# PN73xxAU register map
File version: 2
CPU: CM0 r0p0, little endian, no MPU, no FPU, 2 interrupt priority bits
Registers are 32-bit, read-write, reset 0x0 unless marked. A register's access mark holds for its fields unless they carry their own. Offsets are from the block's base; [hi:lo] are bit positions; {n}, {i} and the like mark numbered series.

## CLIF (part 2 of 2) — Contactless Interface Frontend
Base 0x40004000
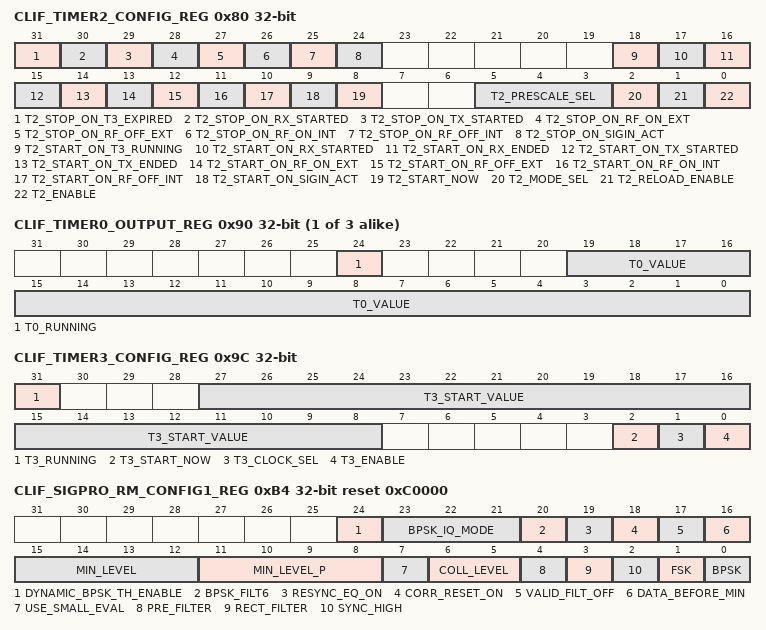
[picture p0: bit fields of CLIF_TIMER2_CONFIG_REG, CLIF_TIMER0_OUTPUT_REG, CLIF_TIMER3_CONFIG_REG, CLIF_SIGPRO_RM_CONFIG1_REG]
0x80 CLIF_TIMER2_CONFIG_REG — CLTimer register
  [31] T2_STOP_ON_T3_EXPIRED — T2_STOP_EVENT: If set. the timer T2 is stopped when timer T3 raises its expiration flag.
  [30] T2_STOP_ON_RX_STARTED — T2_STOP_EVENT: If set. the timer T2 is stopped when a data reception begins (1st bit is received).
  [29] T2_STOP_ON_TX_STARTED — T2_STOP_EVENT: If set. the timer T2 is stopped when a data transmission begins.
  [28] T2_STOP_ON_RF_ON_EXT — T2_STOP_EVENT: If set. the timer T2 is stopped when the external RF field is detected.
  [27] T2_STOP_ON_RF_OFF_EXT — T2_STOP_EVENT: If set. the timer T2 is stopped when the external RF field vanishes.
  [26] T2_STOP_ON_RF_ON_INT — T2_STOP_EVENT: If set. the timer T2 is stopped when the internal RF field is turned on.
  [25] T2_STOP_ON_RF_OFF_INT — T2_STOP_EVENT: If set. the timer T2 is stopped when the internal RF field is turned off.
  [24] T2_STOP_ON_SIGIN_ACT — T2_STOP_EVENT: If set. the timer T2 is stopped when an activity on SigIn is detected.
  [18] T2_START_ON_T3_RUNNING — T2_START_EVENT: If set. the timer T2 is started when timer T3 has started.
  [17] T2_START_ON_RX_STARTED — T2_START_EVENT: If set. the timer T2 is started when a data reception begins (1st bit is received).
  [16] T2_START_ON_RX_ENDED — T2_START_EVENT: If set. the timer T2 is started when a data reception ends.
  [15] T2_START_ON_TX_STARTED — T2_START_EVENT: If set. the timer T2 is started when a data transmission begins.
  [14] T2_START_ON_TX_ENDED — T2_START_EVENT: If set. the timer T2 is started when a data transmission ends.
  [13] T2_START_ON_RF_ON_EXT — T2_START_EVENT: If set. the timer T2 is started when the external RF field is detected.
  [12] T2_START_ON_RF_OFF_EXT — T2_START_EVENT: If set. the timer T2 is started when the external RF field is not detected any more.
  [11] T2_START_ON_RF_ON_INT — T2_START_EVENT: If set. the timer T2 is started when an internal RF field is turned on.
  [10] T2_START_ON_RF_OFF_INT — T2_START_EVENT: If set. the timer T2 is started when an internal RF field is turned off.
  [9] T2_START_ON_SIGIN_ACT — T2_START_EVENT: If set. the timer T2 is started when an activity on SigIn is detected.
  [8] T2_START_NOW — T2_START_EVENT: If set. the timer T2 is started immediatly.
  [5:3] T2_PRESCALE_SEL — Controls frequency/period of the timer T2 when the prescaler is activated by T2_MODE_SEL. 000b* 6.78MHz counter 001b 3.39MHz counter 010b 1.70MHz counter 011b 848kHz counter 100b 424kHz counter 101b 212kHz counter 110b 106kHz counter 111b 53kHz counter
  [2] T2_MODE_SEL — If set. the timer T2 is started the prescaler for the timer T2 is enabled. 0* Prescaler is disabled: the timer frequency matches CLIF clock frequency (13.56MHz). 1 Prescaler is enabled: the timer operates on the prescaler signal frequency (chosen by T2_PRESCALE_SEL).
  [1] T2_RELOAD_ENABLE — If set to 0.the timer T2 will stop on expiration. 0* After expiration the timer T2 will stop counting. i.e.. remain zero. reset value. 1 After expiration the timer T2 will reload its preset value and continue counting down.
  [0] T2_ENABLE — Enables the timer T2
{0x84+4i} CLIF_TIMER{i}_RELOAD_REG (i=0..2) — CLTimer register
  [19:0] T{i}_RELOAD_VALUE — Reload value of the timer T{i}.
{0x90+4i} CLIF_TIMER{i}_OUTPUT_REG ro (i=0..2) — CLTimer register
  [24] T{i}_RUNNING — Indicates that timer T{i} is running (busy)
  [19:0] T{i}_VALUE — Value of 20bit counter in timer T{i}
0x9C CLIF_TIMER3_CONFIG_REG — CLTimer register
  [31] T3_RUNNING ro — Indicates that timer T3 is running (busy)
  [27:8] T3_START_VALUE — Start value of timer T3
  [2] T3_START_NOW — Start event for T3
  [1] T3_CLOCK_SEL — Select the timer clock frequency 0 HFO clock 1 LFO clock
  [0] T3_ENABLE — Enables timer T3
0xAC CLIF_SIGPRO_CONFIG_REG — SigPro register
  [31:0] INTERNAL_USE_0_31 — Internal Use
0xB0 CLIF_SIGPRO_RM_CONFIG0_REG — SigPro register
  [31:0] INTERNAL_USE_0_31 — Internal Use
0xB4 CLIF_SIGPRO_RM_CONFIG1_REG reset 0xC0000 — SigPro register
  [24] DYNAMIC_BPSK_TH_ENABLE — If set to 1 the threshold for BPSK demodulation is dynamically adapted while reception. Note: This setting is only valid in BSPK modes - otherwise it is ignored
  [23:21] BPSK_IQ_MODE — 000*-111 Defines strategy of signal processing regarding I and Q channel 000* Both channels (I and Q) are used for signal processing 001 Use only I channel 010 Use only Q channel 011 RFU 100 Use the strongest channel 101 Use the first channel 110-111 RFU
  [20] BPSK_FILT6 — This bit changes the Spike filter for the Phaseshift detection from order 5 to order 6 (default = order 6).
  [19] RESYNC_EQ_ON — Resynchronisaton during the SOF for an equal correlation value is done (default = activated).
  [18] CORR_RESET_ON — The correclator is reset at a reset (default = activated).
  [17] VALID_FILT_OFF — Disables a special filter in BPSK mode. If set to 0 the correlation of 0110 is filtered with the correlation of 1110 and 0111. Otherwise the demodulation is done using the correlation with 0110
  [16] DATA_BEFORE_MIN — Data is received even before the first minimum at the SOF (default: = deactivated).
  [15:12] MIN_LEVEL — Defines the MinLevel of the reception Note: The MinLevel should be higher than the noise level in the system Note: Used for BPSK and Manchester with Subcarrier communication types as MinLevel!
  [11:8] MIN_LEVEL_P — Defines the minlevel for the phaseshift detector unit
  [7] USE_SMALL_EVAL — Defines the length of the eval periode for the correlator for Manchester subcarrier communication types.
  [6:5] COLL_LEVEL — Defines how strong a signal must be to be interpreded as a collision for Manchester subcarrier communication types. 00* >12.5% 01 >25% 10 >50% No Collison
  [4] PRE_FILTER — If set to 1 four samples are combined to one data. (average)
  [3] RECT_FILTER — If set to one. the ADC-values are changed to a more rectangular waveshape.
  [2] SYNC_HIGH — Defines if the bitgrid is fixed at maximum (1) or at a minimum(0) value of the correlation.
  [1] FSK — If set to 1. the demodulation scheme is FSK.
  [0] BPSK — If set to 1 the demodulation scheme is BPSK.
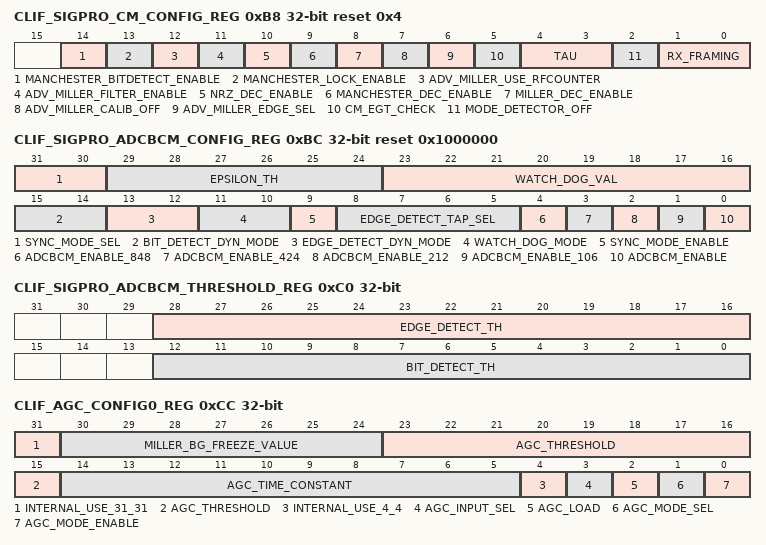
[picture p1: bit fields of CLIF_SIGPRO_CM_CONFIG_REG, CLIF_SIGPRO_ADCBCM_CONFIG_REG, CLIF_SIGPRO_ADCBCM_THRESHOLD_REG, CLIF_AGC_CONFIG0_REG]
0xB8 CLIF_SIGPRO_CM_CONFIG_REG reset 0x4 — SigPro register
  [14] MANCHESTER_BITDETECT_ENABLE — Enables the new method to for baudrate detection.
  [13] MANCHESTER_LOCK_ENABLE — Enables the new method to freeze the subcarrier signal after the preamble.
  [12] ADV_MILLER_USE_RFCOUNTER — If set the Adv. Miller decoder uses the RF counter directly for decoding. This feature is intended for 848kBd to avoid additional errors due to synchronization.
  [11] ADV_MILLER_FILTER_ENABLE — If set the Miller input signal is filtered with a 3-out-of-5 median filter (on HFO clock) before decoding. Note: This feature is not available in combination with ADV_MILLER_USE_RFCOUNTER.
  [10] NRZ_DEC_ENABLE — If set the NRZ decoder is activated for ISO14443 type B PICC reception. Note that the NRZ decoder must be activated in general target mode to be able to detect ISO14443 type B.
  [9] MANCHESTER_DEC_ENABLE — If set the Manchester decoder is activated for FeliCa PICC reception. Note that the Manchester decoder must be activated in general target mode to be able to detect FeliCa.
  [8] MILLER_DEC_ENABLE — If set the Miller decoder is activated for ISO14443 type A PICC reception. Note that the Miller decoder must be activated in general target mode to be able to detect ISO14443 type A.
  [7] ADV_MILLER_CALIB_OFF — If set the calibration of the advanced Miller decoder is deactivated and the nominal threshold values are used.
  [6] ADV_MILLER_EDGE_SEL — Select the edge for decoding Note: This feature is not available in combination with ADV_MILLER_USE_RFCOUNTER. 0* decoder counts from falling to falling edge: 1 decoder counts from rising to rising edge.
  [5] CM_EGT_CHECK — If set the EGT check for ISO14443 type B card-mode is activated. An invalid EGT length causes an protocol error.
  [4:3] TAU — Defines the timing constant of the internal PLL as a negative power of two.
  [2] MODE_DETECTOR_OFF — If set to 1. the mode detector is deactivated
  [1:0] RX_FRAMING — Defines the framing in card mode. Note that these bits are set by the mod-detector if automatic mode detection is enabled and the communication mode is detected. 00* ISO14443A / Mifare 01 ISO18092 (NFC - with Syncbyte 0xF0) 10 FeliCa 11 ISO14443B
0xBC CLIF_SIGPRO_ADCBCM_CONFIG_REG reset 0x1000000 — SigPro register
  [31:30] SYNC_MODE_SEL — Chooses the threshold for interpolation of the zero-crossing detection. 0h 0.25. 1h 0.5. 2h-3h 0.75
  [29:24] EPSILON_TH — Threshold for the epsilon environment in the zero-crossing detection block. Note that with value 1h the block is disabled and the value 0h is forbidden.
  [23:16] WATCH_DOG_VAL — Reset value for the Watch-Dog Counter.After this number of 848kHz clock cycles where no edges was detected the Watch Dog counter resets the edge-locking the output envelope and the dynamic threshold.
  [15:14] BIT_DETECT_DYN_MODE — Defines the dynamic bit detector adaptation. For dynamic threshold adaptation the minimum threshold is defined in CLIF_SIGPRO_ADCBCM_THRESHOLD_REG 00 Static bit detection 01 Dynamic edge detection 25% from last decision 10 Dynamic edge detection 50% from last decision 11 Dynamic edge detection 75% from last decision
  [13:12] EDGE_DETECT_DYN_MODE — Defines the dynamic edge detector adaptation. For dynamic threshold adaptation the minimum threshold is defined in CLIF_SIGPRO_ADCBCM_THRESHOLD_REG 00 Static edge detection 01 Dynamic edge detection 25% from last decision 10 Dynamic edge detection 50% from last decision 11 Dynamic edge detection 75% from last decision
  [11:10] WATCH_DOG_MODE — Selects mode of the watch-dog timer. 00 Watch-dog timer disabled 01 Watch dog timer with edge-detection as input (as for PN547/548) 10 Watch dog timer with valid-signal as input 11 Watch dog timer with valid-signal as input
  [9] SYNC_MODE_ENABLE — If set. the sync mode is activated. The sync-mode is used to reduce the jitter in the zero-crossing detection (usage depends on the analog HW configuration).
  [8:5] EDGE_DETECT_TAP_SEL — Selects the number of taps of the edge-detector filter. 0000* Edge detector filter with 2 taps 0001 Edge detector filter with 4 taps 0010 Edge detector filter with 6 taps 0011 Edge detector filter with 8 taps 0100 Edge detector filter with 10 taps 0101 Edge detector filter with 12 taps 0110 Edge detector filter with 14 taps 0111 Edge detector filter with 16 taps 1000 Edge detector filter with 18 taps 1001 Edge detector filter with 20 taps 1010 Edge detector filter with 22 taps 1011 Edge detector filter with 24 taps 1100 Edge detector filter with 26 taps 1101 Edge detector filter with 28 taps 1110 Edge detector filter with 30 taps 1111 Edge detector filter with 32 taps
  [4] ADCBCM_ENABLE_848 — Enables the 848kBd envelope detection of the ADCBCM.
  [3] ADCBCM_ENABLE_424 — Enables the 424kBd envelope detection of the ADCBCM. At start up for mode-detection this mode has to be enabled.
  [2] ADCBCM_ENABLE_212 — Enables the 212kBd envelope detection of the ADCBCM. At start up for mode-detection this mode has to be enabled.
  [1] ADCBCM_ENABLE_106 — Enables the 106kBd envelope detection of the ADCBCM. At start up for mode-detection this mode has to be enabled.
  [0] ADCBCM_ENABLE — Enables the ADCBCM. Note that at least one mode (106. 212. 424. or 848kBd) has to enabled additionally.
0xC0 CLIF_SIGPRO_ADCBCM_THRESHOLD_REG — SigPro register
  [28:16] EDGE_DETECT_TH — Threshold for the edge decision block of the ADCBCM.
  [12:0] BIT_DETECT_TH — Threshold for the bit decision block of the ADCBCM.
0xC4 CLIF_SIGPRO_ADCBCM_RFU1 ro — SigPro register
  [31:0] INTERNAL_USE_0_31 — Internal Use
0xC8 CLIF_SIGPRO_ADCBCM_RFU2 ro — SigPro register
  [31:0] INTERNAL_USE_0_31 — Internal Use
0xCC CLIF_AGC_CONFIG0_REG — AGC register
  [31] INTERNAL_USE_31_31 — Internal Use
  [30:24] MILLER_BG_FREEZE_VALUE — This bit is primarily intended to achieve AGC operation in RM for ISO14443 type A 106kBd (AGC_FREEZE_ON_MILLER_BG). However this field is also re-used for the back-up modes AGC_FREEZE_ON_RX_WAIT and AGC_FAST_MODE_RX_WAIT.
  [23:15] AGC_THRESHOLD — Defines the threshold value for the AGC. Value must not be larger than AGC_TIME_CONSTANT>>1 - 1.
  [14:5] AGC_TIME_CONSTANT — Time constant for the AGC update. An AGC period is given by (AGC_TIME_CONSTANT+1 ) * 13.56MHz
  [4] INTERNAL_USE_4_4 — Internal Use
  [3] AGC_INPUT_SEL — Selects the AGC value to be loaded into the AGC and the scource for manual mode: 0* CLIF_AGC_INPUT_REG.AGC_CM_VALUE 1 CLIF_AGC_INPUT_REG.AGC_RM_VALUE
  [2] AGC_LOAD wo — If set. one AGC control value is loaded from CLIF_RSSI_REG .into the internal AGC register (depending on AGC_INPUT_SEL).
  [1] AGC_MODE_SEL — Selects the operation mode of the AGC: 0* Rx-Divider is controlled by the register CLIF_AGC_INPUT_REG.AGC_CM_VALUE or CLIF_AGC_INPUT_REG.AGC_RM_VALUE (dependent on AGC_INPUT_SEL) 1 Rx-Divider value is controlled by the AGC.
  [0] AGC_MODE_ENABLE — If set the AGC is enabled. If not set the Rx-Divider is controlled by either the internal AGC register or a register value (dependent on AGC_MODE_SEL).
0xD0 CLIF_AGC_CONFIG1_REG — AGC register
  [31:0] INTERNAL_USE_0_31 — Internal Use
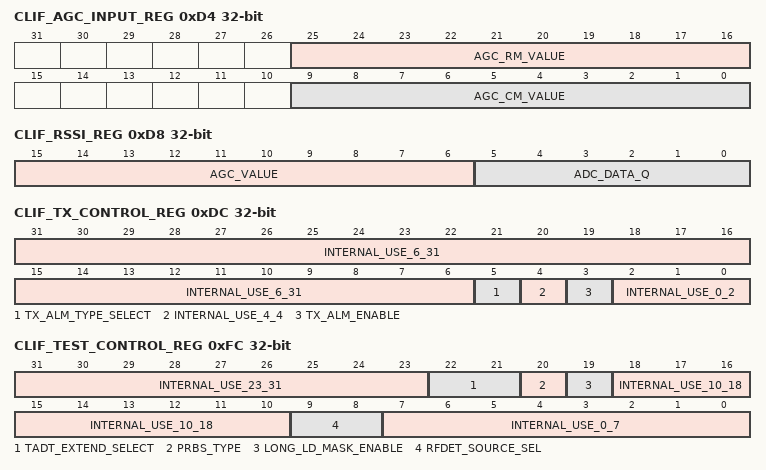
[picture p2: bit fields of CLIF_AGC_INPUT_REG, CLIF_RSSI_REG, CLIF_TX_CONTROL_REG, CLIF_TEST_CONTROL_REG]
0xD4 CLIF_AGC_INPUT_REG — AGC register
  [25:16] AGC_RM_VALUE — Static AGC value used for reader mode
  [9:0] AGC_CM_VALUE — Static AGC value used for card mode
0xD8 CLIF_RSSI_REG ro — AGC register
  [15:6] AGC_VALUE — RSSI: Current value of the AGC
  [5:0] ADC_DATA_Q — RSSI: Q-channel ADC value (for RSSI DC coupling shall be used)
0xDC CLIF_TX_CONTROL_REG — TX Control Register
  [31:6] INTERNAL_USE_6_31 ro — Internal Use
  [5] TX_ALM_TYPE_SELECT — Defines which ALM type is used. If set to 1 Dual-Loop-ALM is used default (0) is Single-Loop-ALM.
  [4] INTERNAL_USE_4_4 — Internal Use
  [3] TX_ALM_ENABLE — If set to 1 ALM is used for transmission in card mode
  [2:0] INTERNAL_USE_0_2 — Internal Use
0xEC CLIF_RX_DATA_BUFFER_REG ro — BufferManager Rx data register
  [31:0] RX_DATA_BUFFER — Data buffer for APB based BufferManager data transfer.
0xFC CLIF_TEST_CONTROL_REG — Test option register
  [31:23] INTERNAL_USE_23_31 — Internal Use
  [22:21] TADT_EXTEND_SELECT — By setting a value != 0 the minimum time for TADT can be increased
  [20] PRBS_TYPE — Defines the PRBS type. If set to 1 PRBS15 is selected default value 0 selects PRBS9
  [19] LONG_LD_MASK_ENABLE — If set to 1 the masking time for the NFC-LD after TxRFOff is longer.
  [18:10] INTERNAL_USE_10_18 — Internal Use
  [9:8] RFDET_SOURCE_SEL — Select the source for RF-Field detection. 0* -> NFC-Level detector indication signal is used. 1 -> RF-Level detector indication signal is used 2. -> NFC- and RF-Level detector indication signal is used 3. -> Override - RF-Field detected is emulated
  [7:0] INTERNAL_USE_0_7 — Internal Use
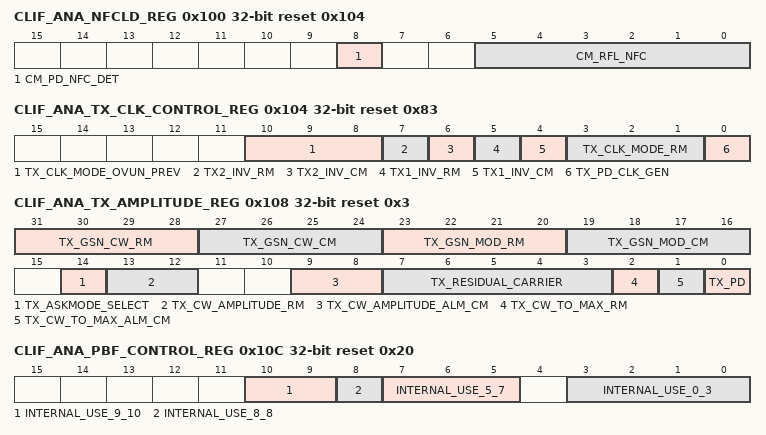
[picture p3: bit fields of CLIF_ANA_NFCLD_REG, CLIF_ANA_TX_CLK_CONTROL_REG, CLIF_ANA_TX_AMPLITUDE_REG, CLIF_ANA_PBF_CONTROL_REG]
0x100 CLIF_ANA_NFCLD_REG reset 0x104 — NFC Level Detector Control Register
  [8] CM_PD_NFC_DET — Power Down NFC level detector
  [5:0] CM_RFL_NFC — Programming of detection level
0x104 CLIF_ANA_TX_CLK_CONTROL_REG reset 0x83 — Analog TX Clock control register
  [10:8] TX_CLK_MODE_OVUN_PREV — Defines the TX clockmode for the period the overshoot/undershoot prevention is active
  [7] TX2_INV_RM — If 1 -> TX output is inverted (clk_13m56_n is used). 0 -> clk_13m56 is used
  [6] TX2_INV_CM — If 1 -> TX output is inverted (clk_13m56_n is used). 0 -> clk_13m56 is used
  [5] TX1_INV_RM — If 1 -> TX output is inverted (clk_13m56_n is used). 0 -> clk_13m56 is used
  [4] TX1_INV_CM — If 1 -> TX output is inverted (clk_13m56_n is used). 0 -> clk_13m56 is used
  [3:1] TX_CLK_MODE_RM — TX clockmode
  [0] TX_PD_CLK_GEN — TX clock generation disabled and thus also envelope synchronization to clk is disabled.
0x108 CLIF_ANA_TX_AMPLITUDE_REG reset 0x3 — Analog TX amplitude control register
  [31:28] TX_GSN_CW_RM — gsn setting at continuous wave in reader mode
  [27:24] TX_GSN_CW_CM — gsn setting at continuous wave in card mode
  [23:20] TX_GSN_MOD_RM — gsn setting at continuous wave in reader mode
  [19:16] TX_GSN_MOD_CM — gsn setting at continuous wave in card mode
  [14] TX_ASKMODE_SELECT — Selects the output voltage mode of the transmitter. Note: This bitfield is new on PN549 default value is 1! 0: Setting used for ALM mode. Tx output voltage is independent of the envelope and hence the TX output amplitude can be adjusted by the bitfield TX_RESIDUAL_CARRIER. 1: Setting used for standard modes (reader and active mode)
  [13:12] TX_CW_AMPLITUDE_RM — set amplitude of unmodulated carrier at reader mode
  [9:8] TX_CW_AMPLITUDE_ALM_CM — set amplitude of unmodulated carrier at card mode
  [7:3] TX_RESIDUAL_CARRIER — set residual carrier (0=100% 1F = 0%)
  [2] TX_CW_TO_MAX_RM — TX HI output is the maximum voltage obtainable from charge pump (RM setting). if set to 1 -> TX_CW_AMPLITUDE_RM is overruled.
  [1] TX_CW_TO_MAX_ALM_CM — TX HI output is the maximum voltage obtainable from charge pump (CM setting). if set to 1 -> TX_CW_AMPLITUDE_CM is overruled.
  [0] TX_PD — charge pumps clamped to tvdd
0x10C CLIF_ANA_PBF_CONTROL_REG reset 0x20 — Analog PbF control register
  [10:9] INTERNAL_USE_9_10 — Internal Use
  [8] INTERNAL_USE_8_8 wo — Internal Use
  [7:5] INTERNAL_USE_5_7 — Internal Use
  [3:0] INTERNAL_USE_0_3 — Internal Use
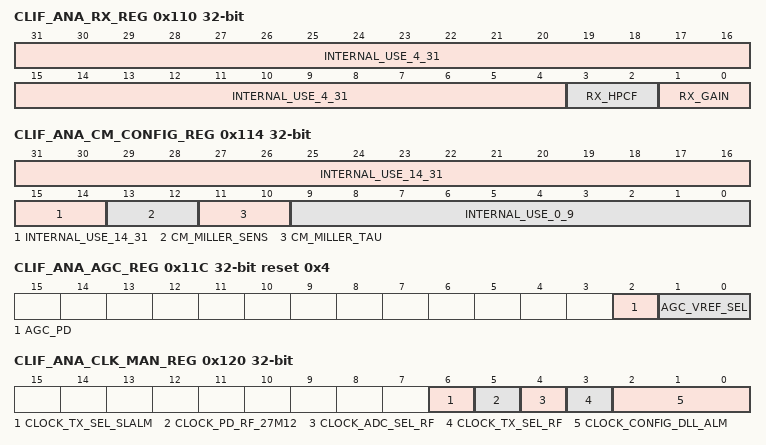
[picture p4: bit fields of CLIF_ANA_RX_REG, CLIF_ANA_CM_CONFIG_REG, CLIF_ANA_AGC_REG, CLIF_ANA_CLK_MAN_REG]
0x110 CLIF_ANA_RX_REG — Analog RM receiver control register
  [31:4] INTERNAL_USE_4_31 — Internal Use
  [3:2] RX_HPCF — Lower Corner Frequency: 00->45kHz 01->85kHz 10->150kHz 11->250kHz
  [1:0] RX_GAIN — Gain Adjustment BBA: 00->33dB 01->40dB 10->50dB 11->57dB
0x114 CLIF_ANA_CM_CONFIG_REG — Analog CM control register
  [31:14] INTERNAL_USE_14_31 — Internal Use
  [13:12] CM_MILLER_SENS — Configuration bits for reference level of Miller demodulator
  [11:10] CM_MILLER_TAU — Configuration bits for the time constant of the reference generation in Miller demodulator
  [9:0] INTERNAL_USE_0_9 — Internal Use
0x11C CLIF_ANA_AGC_REG reset 0x4 — Analog AGC control register
  [2] AGC_PD — AGC power down
  [1:0] AGC_VREF_SEL — Select the comparison reference voltage
0x120 CLIF_ANA_CLK_MAN_REG — Analog clock management control Register
  [6] CLOCK_TX_SEL_SLALM — Selects DPLL
  [5] CLOCK_PD_RF_27M12 — Power down RF clock generation
  [4] CLOCK_ADC_SEL_RF — Select RF clock for ADC from DLL or PLL
  [3] CLOCK_TX_SEL_RF — Select DLL clock for TX (instead of PLL clock)
  [2:0] CLOCK_CONFIG_DLL_ALM — Select DLL clock phase
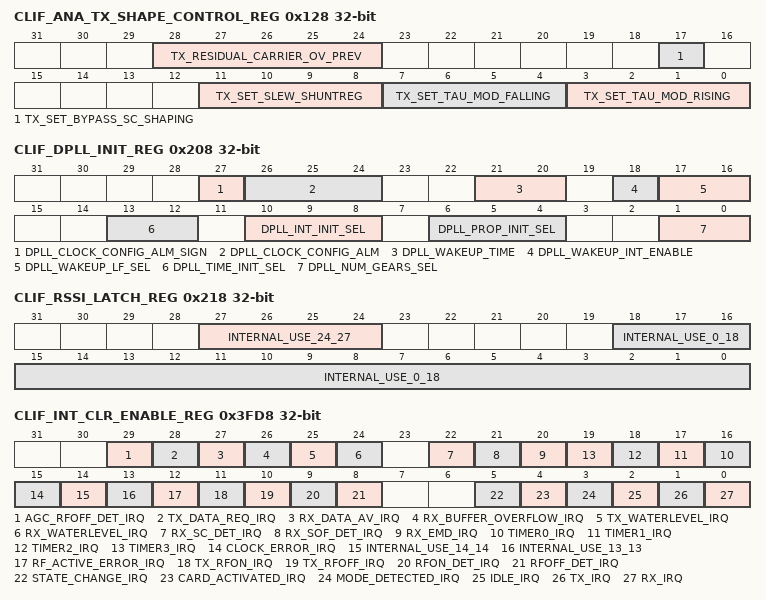
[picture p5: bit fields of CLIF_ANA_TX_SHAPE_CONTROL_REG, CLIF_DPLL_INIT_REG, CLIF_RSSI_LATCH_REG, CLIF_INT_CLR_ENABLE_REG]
0x128 CLIF_ANA_TX_SHAPE_CONTROL_REG — Analog TX shaping control register
  [28:24] TX_RESIDUAL_CARRIER_OV_PREV — Defines the value for the residual carrier for the period the overshoot prevention pattern is active.
  [17] TX_SET_BYPASS_SC_SHAPING — Bypasses switched capacitor shaping of the Transmitter Signal
  [11:8] TX_SET_SLEW_SHUNTREG — Set slew rate for shunt regulator
  [7:4] TX_SET_TAU_MOD_FALLING — Transmitter TAU setting for falling edge of modulation shape. In AnalogControl module the output signal is switched with the tx_envelope. Only valid is TX_SET_SINGLE_CP_MODE is set
  [3:0] TX_SET_TAU_MOD_RISING — Transmitter TAU setting for rising edge of modulation shape. In AnalogControl module the output signal is switched with the tx_envelope. Only valid is TX_SET_SINGLE_CP_MODE is set
0x1FC CLIF_ANA_TEST_REG — Analog test control register
  [0] TX_CW_AMP_REF2TVDD — If set to 1 the reference of the unmodulated carrier is defined relative to TVDDNote: Do not change in normal operation
0x204 CLIF_DPLL_CONTROL_REG — DPLL Control Register
  [31:0] INTERNAKL_USE_0 ro — Internal Use
0x208 CLIF_DPLL_INIT_REG — DPLL Configuration Register
  [27] DPLL_CLOCK_CONFIG_ALM_SIGN — Defines the sign of the fine phase-changes (positive or negative).
  [26:24] DPLL_CLOCK_CONFIG_ALM — Is the fine tuning of the phase configuration done on top of the coarse setting CLIF_ANA_CLK_MAN_REG.CLOCK_CONFIG_DLL_ALM
  [21:20] DPLL_WAKEUP_TIME — Duration of the Wakeup-Mode
  [18] DPLL_WAKEUP_INT_ENABLE — Enables the integral path of the loop-filter even in WAKEUP mode
  [17:16] DPLL_WAKEUP_LF_SEL — Proportional parameter of loop filter for WAKEUP mode
  [13:12] DPLL_TIME_INIT_SEL — Initial gear duration
  [10:8] DPLL_INT_INIT_SEL — Initial gear integral parameter
  [6:4] DPLL_PROP_INIT_SEL — Initial gear proportional parameter
  [1:0] DPLL_NUM_GEARS_SEL — Defines the number of gears
0x20C CLIF_DPLL_GEAR_REG — DPLL Configuration Register
  [31:0] INTERNAL_USE_0_31 — Internal Use
0x210 CLIF_DPLL_INIT_FREQ_REG — DPLL Configuration Register
  [31:0] INTERNAL_USE_0_31 — Internal Use
0x214 CLIF_BBA_CONTROL_REG — BBA Control Register
  [31:0] INTERNAL_USE_0_31 — Internal Use
0x218 CLIF_RSSI_LATCH_REG — Register to configure/read RSSI latch
  [27:24] INTERNAL_USE_24_27 — Internal Use
  [18:0] INTERNAL_USE_0_18 ro — Internal Use
0x3FD8 CLIF_INT_CLR_ENABLE_REG wo — Interrupt register
  [29] AGC_RFOFF_DET_IRQ — Writing 1 to this register does clear the corresponding IRQ ENABLE flag
  [28] TX_DATA_REQ_IRQ — Writing 1 to this register does clear the corresponding IRQ ENABLE flag
  [27] RX_DATA_AV_IRQ — Writing 1 to this register does clear the corresponding IRQ ENABLE flag
  [26] RX_BUFFER_OVERFLOW_IRQ — Writing 1 to this register does clear the corresponding IRQ ENABLE flag
  [25] TX_WATERLEVEL_IRQ — Writing 1 to this register does clear the corresponding IRQ ENABLE flag
  [24] RX_WATERLEVEL_IRQ — Writing 1 to this register does clear the corresponding IRQ ENABLE flag
  [22] RX_SC_DET_IRQ — Writing 1 to this register does clear the corresponding IRQ ENABLE flag
  [21] RX_SOF_DET_IRQ — Writing 1 to this register does clear the corresponding IRQ ENABLE flag
  [20] RX_EMD_IRQ — Writing 1 to this register does clear the corresponding IRQ ENABLE flag
  [n+16] TIMER{n}_IRQ (n=0..3) — Writing 1 to this register does clear the corresponding IRQ ENABLE flag
  [15] CLOCK_ERROR_IRQ — Writing 1 to this register does clear the corresponding IRQ ENABLE flag
  [14] INTERNAL_USE_14_14 — Internal Use
  [13] INTERNAL_USE_13_13 — Internal Use
  [12] RF_ACTIVE_ERROR_IRQ — Writing 1 to this register does clear the corresponding IRQ ENABLE flag
  [11] TX_RFON_IRQ — Writing 1 to this register does clear the corresponding IRQ ENABLE flag
  [10] TX_RFOFF_IRQ — Writing 1 to this register does clear the corresponding IRQ ENABLE flag
  [9] RFON_DET_IRQ — Writing 1 to this register does clear the corresponding IRQ ENABLE flag
  [8] RFOFF_DET_IRQ — Writing 1 to this register does clear the corresponding IRQ ENABLE flag
  [5] STATE_CHANGE_IRQ — Writing 1 to this register does clear the corresponding IRQ ENABLE flag
  [4] CARD_ACTIVATED_IRQ — Writing 1 to this register does clear the corresponding IRQ ENABLE flag
  [3] MODE_DETECTED_IRQ — Writing 1 to this register does clear the corresponding IRQ ENABLE flag
  [2] IDLE_IRQ — Writing 1 to this register does clear the corresponding IRQ ENABLE flag
  [1] TX_IRQ — Writing 1 to this register does clear the corresponding IRQ ENABLE flag
  [0] RX_IRQ — Writing 1 to this register does clear the corresponding IRQ ENABLE flag
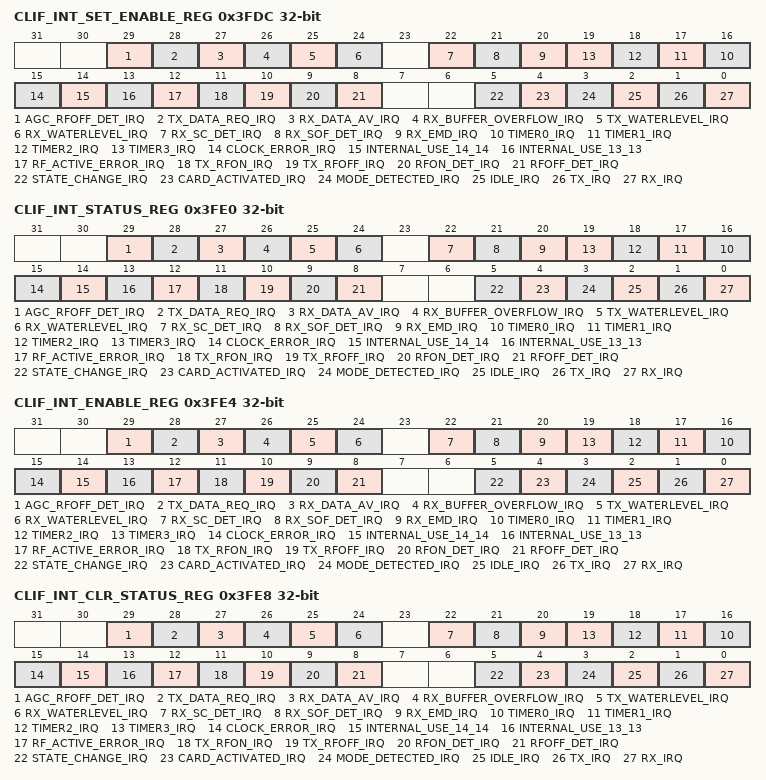
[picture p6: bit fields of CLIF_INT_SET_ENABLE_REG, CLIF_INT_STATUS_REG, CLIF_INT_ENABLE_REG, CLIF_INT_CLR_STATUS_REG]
0x3FDC CLIF_INT_SET_ENABLE_REG wo — Interrupt register
  [29] AGC_RFOFF_DET_IRQ — Writing 1 to this register does set the corresponding IRQ ENABLE flag
  [28] TX_DATA_REQ_IRQ — Writing 1 to this register does set the corresponding IRQ ENABLE flag
  [27] RX_DATA_AV_IRQ — Writing 1 to this register does set the corresponding IRQ ENABLE flag
  [26] RX_BUFFER_OVERFLOW_IRQ — Writing 1 to this register does set the corresponding IRQ ENABLE flag
  [25] TX_WATERLEVEL_IRQ — Writing 1 to this register does set the corresponding IRQ ENABLE flag
  [24] RX_WATERLEVEL_IRQ — Writing 1 to this register does set the corresponding IRQ ENABLE flag
  [22] RX_SC_DET_IRQ — Writing 1 to this register does set the corresponding IRQ ENABLE flag
  [21] RX_SOF_DET_IRQ — Writing 1 to this register does set the corresponding IRQ ENABLE flag
  [20] RX_EMD_IRQ — Writing 1 to this register does set the corresponding IRQ ENABLE flag
  [n+16] TIMER{n}_IRQ (n=0..3) — Writing 1 to this register does set the corresponding IRQ ENABLE flag
  [15] CLOCK_ERROR_IRQ — Writing 1 to this register does set the corresponding IRQ ENABLE flag
  [14] INTERNAL_USE_14_14 — Internal Use
  [13] INTERNAL_USE_13_13 — Internal Use
  [12] RF_ACTIVE_ERROR_IRQ — Writing 1 to this register does set the corresponding IRQ ENABLE flag
  [11] TX_RFON_IRQ — Writing 1 to this register does set the corresponding IRQ ENABLE flag
  [10] TX_RFOFF_IRQ — Writing 1 to this register does set the corresponding IRQ ENABLE flag
  [9] RFON_DET_IRQ — Writing 1 to this register does set the corresponding IRQ ENABLE flag
  [8] RFOFF_DET_IRQ — Writing 1 to this register does set the corresponding IRQ ENABLE flag
  [5] STATE_CHANGE_IRQ — Writing 1 to this register does set the corresponding IRQ ENABLE flag
  [4] CARD_ACTIVATED_IRQ — Writing 1 to this register does set the corresponding IRQ ENABLE flag
  [3] MODE_DETECTED_IRQ — Writing 1 to this register does set the corresponding IRQ ENABLE flag
  [2] IDLE_IRQ — Writing 1 to this register does set the corresponding IRQ ENABLE flag
  [1] TX_IRQ — Writing 1 to this register does set the corresponding IRQ ENABLE flag
  [0] RX_IRQ — Writing 1 to this register does set the corresponding IRQ ENABLE flag
0x3FE0 CLIF_INT_STATUS_REG ro — Interrupt register
  [29] AGC_RFOFF_DET_IRQ — Set to 1 by HW when the AGC has detected the external RF-Field was switched off while transmitting in SL-ALM mode. Note: Only valid if the detection mode is enabled with the register bit-field AGC_RF_DETECT_SEL
  [28] TX_DATA_REQ_IRQ — Set to 1 by HW when the BufferManager requests data for transmission from RAM. Note: Only valid if the bit DIRECT_DATA_ACCESS_ENABLE is set to 1
  [27] RX_DATA_AV_IRQ — Set to 1 by HW when the BufferManager holds received data from reception to be written to RAM. Note: Only valid if the bit DIRECT_DATA_ACCESS_ENABLE is set to 1
  [26] RX_BUFFER_OVERFLOW_IRQ — Set to 1 by HW when the number of bytes received exceds the size of the RX buffer. Note: Reception is stoped in that case. Note: If RX_MULTIPLE is set to 1 this an this IRQ is raised when the sum of all frames exceed the RX buffer size
  [25] TX_WATERLEVEL_IRQ — Set to 1 by HW when the number of bytes transmitted is equal to the TX_WATERLEVEL
  [24] RX_WATERLEVEL_IRQ — Set to 1 by HW when the number of bytes received is equal to the RX_WATERLEVEL
  [22] RX_SC_DET_IRQ — Set to 1 by HW when in reader mode a subcarrier is detected
  [21] RX_SOF_DET_IRQ — Set to 1 by HW when in reader mode an SOF is detected
  [20] RX_EMD_IRQ — Set to 1 by HW when an EMD event is detected
  [n+16] TIMER{n}_IRQ (n=0..3) — Set to 1 by HW when the Timer{n} is expired.
  [15] CLOCK_ERROR_IRQ — Set to 1 by HW when RF-Field vanished (and consequently the RF-Clock is not present) and the clock of the system PLL is not available
  [14] INTERNAL_USE_14_14 — Internal Use
  [13] INTERNAL_USE_13_13 — Internal Use
  [12] RF_ACTIVE_ERROR_IRQ — Set to 1 by HW when an RF error case occurred
  [11] TX_RFON_IRQ — Set to 1 by HW when the internally generated RF-field was switched on.
  [10] TX_RFOFF_IRQ — Set to 1 by HW when the internally generated RF-field was switched off.
  [9] RFON_DET_IRQ — Set to 1 by HW when an external RF-field is detected.
  [8] RFOFF_DET_IRQ — Set to 1 by HW when an until then preset external RF-field is switched off.
  [5] STATE_CHANGE_IRQ — Set to 1 by HW when a transceive state is entered selected in the register field STATE_TRIGGER_SELECT
  [4] CARD_ACTIVATED_IRQ — Set to 1 by HW when TypeA card mode activation FSM reached the ACTIVATED or ACTIVATE_S state
  [3] MODE_DETECTED_IRQ — Set to 1 by HW when the card mode has been detected by the ModeDetector Note: While the TypeA activation FSM is active no IRQ is issued any more
  [2] IDLE_IRQ — Set to 1 by HW when the IDLE state is entered
  [1] TX_IRQ — Set to 1 by HW when an ongoing transmission is finished.
  [0] RX_IRQ — Set to 1 by HW when an ongoing reception is finished
0x3FE4 CLIF_INT_ENABLE_REG ro — Interrupt register
  [29] AGC_RFOFF_DET_IRQ — If this bit is 1 the corresponding IRQ can propergate to the CPUs IRQ controller
  [28] TX_DATA_REQ_IRQ — If this bit is 1 the corresponding IRQ can propergate to the CPUs IRQ controller
  [27] RX_DATA_AV_IRQ — If this bit is 1 the corresponding IRQ can propergate to the CPUs IRQ controller
  [26] RX_BUFFER_OVERFLOW_IRQ — If this bit is 1 the corresponding IRQ can propergate to the CPUs IRQ controller
  [25] TX_WATERLEVEL_IRQ — If this bit is 1 the corresponding IRQ can propergate to the CPUs IRQ controller
  [24] RX_WATERLEVEL_IRQ — If this bit is 1 the corresponding IRQ can propergate to the CPUs IRQ controller
  [22] RX_SC_DET_IRQ — If this bit is 1 the corresponding IRQ can propergate to the CPUs IRQ controller
  [21] RX_SOF_DET_IRQ — If this bit is 1 the corresponding IRQ can propergate to the CPUs IRQ controller
  [20] RX_EMD_IRQ — If this bit is 1 the corresponding IRQ can propergate to the CPUs IRQ controller
  [n+16] TIMER{n}_IRQ (n=0..3) — If this bit is 1 the corresponding IRQ can propergate to the CPUs IRQ controller
  [15] CLOCK_ERROR_IRQ — If this bit is 1 the corresponding IRQ can propergate to the CPUs IRQ controller
  [14] INTERNAL_USE_14_14 — Internal Use
  [13] INTERNAL_USE_13_13 — Internal Use
  [12] RF_ACTIVE_ERROR_IRQ — If this bit is 1 the corresponding IRQ can propergate to the CPUs IRQ controller
  [11] TX_RFON_IRQ — If this bit is 1 the corresponding IRQ can propergate to the CPUs IRQ controller
  [10] TX_RFOFF_IRQ — If this bit is 1 the corresponding IRQ can propergate to the CPUs IRQ controller
  [9] RFON_DET_IRQ — If this bit is 1 the corresponding IRQ can propergate to the CPUs IRQ controller
  [8] RFOFF_DET_IRQ — If this bit is 1 the corresponding IRQ can propergate to the CPUs IRQ controller
  [5] STATE_CHANGE_IRQ — If this bit is 1 the corresponding IRQ can propergate to the CPUs IRQ controller
  [4] CARD_ACTIVATED_IRQ — If this bit is 1 the corresponding IRQ can propergate to the CPUs IRQ controller
  [3] MODE_DETECTED_IRQ — If this bit is 1 the corresponding IRQ can propergate to the CPUs IRQ controller
  [2] IDLE_IRQ — If this bit is 1 the corresponding IRQ can propergate to the CPUs IRQ controller
  [1] TX_IRQ — If this bit is 1 the corresponding IRQ can propergate to the CPUs IRQ controller
  [0] RX_IRQ — If this bit is 1 the corresponding IRQ can propergate to the CPUs IRQ controller
0x3FE8 CLIF_INT_CLR_STATUS_REG wo — Interrupt register
  [29] AGC_RFOFF_DET_IRQ — Writing 1 to this register does clear the corresponding IRQ STATUS flag
  [28] TX_DATA_REQ_IRQ — Writing 1 to this register does clear the corresponding IRQ STATUS flag
  [27] RX_DATA_AV_IRQ — Writing 1 to this register does clear the corresponding IRQ STATUS flag
  [26] RX_BUFFER_OVERFLOW_IRQ — Writing 1 to this register does clear the corresponding IRQ STATUS flag
  [25] TX_WATERLEVEL_IRQ — Writing 1 to this register does clear the corresponding IRQ STATUS flag
  [24] RX_WATERLEVEL_IRQ — Writing 1 to this register does clear the corresponding IRQ STATUS flag
  [22] RX_SC_DET_IRQ — Writing 1 to this register does clear the corresponding IRQ STATUS flag
  [21] RX_SOF_DET_IRQ — Writing 1 to this register does clear the corresponding IRQ STATUS flag
  [20] RX_EMD_IRQ — Writing 1 to this register does clear the corresponding IRQ STATUS flag
  [n+16] TIMER{n}_IRQ (n=0..3) — Writing 1 to this register does clear the corresponding IRQ STATUS flag
  [15] CLOCK_ERROR_IRQ — Writing 1 to this register does clear the corresponding IRQ STATUS flag
  [14] INTERNAL_USE_14_14 — Internal Use
  [13] INTERNAL_USE_13_13 — Internal Use
  [12] RF_ACTIVE_ERROR_IRQ — Writing 1 to this register does clear the corresponding IRQ STATUS flag
  [11] TX_RFON_IRQ — Writing 1 to this register does clear the corresponding IRQ STATUS flag
  [10] TX_RFOFF_IRQ — Writing 1 to this register does clear the corresponding IRQ STATUS flag
  [9] RFON_DET_IRQ — Writing 1 to this register does clear the corresponding IRQ STATUS flag
  [8] RFOFF_DET_IRQ — Writing 1 to this register does clear the corresponding IRQ STATUS flag
  [5] STATE_CHANGE_IRQ — Writing 1 to this register does clear the corresponding IRQ STATUS flag
  [4] CARD_ACTIVATED_IRQ — Writing 1 to this register does clear the corresponding IRQ STATUS flag
  [3] MODE_DETECTED_IRQ — Writing 1 to this register does clear the corresponding IRQ STATUS flag
  [2] IDLE_IRQ — Writing 1 to this register does clear the corresponding IRQ STATUS flag
  [1] TX_IRQ — Writing 1 to this register does clear the corresponding IRQ STATUS flag
  [0] RX_IRQ — Writing 1 to this register does clear the corresponding IRQ STATUS flag
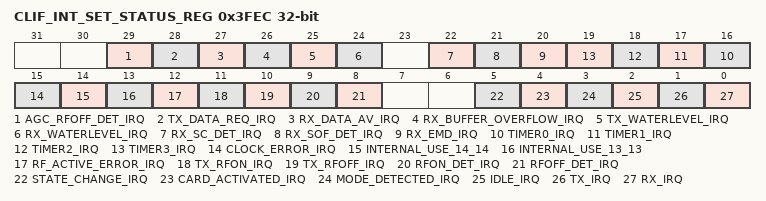
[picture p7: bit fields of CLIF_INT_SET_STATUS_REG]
0x3FEC CLIF_INT_SET_STATUS_REG wo — Interrupt register
  [29] AGC_RFOFF_DET_IRQ — Writing 1 to this register does set the corresponding IRQ STATUS flag
  [28] TX_DATA_REQ_IRQ — Writing 1 to this register does set the corresponding IRQ STATUS flag
  [27] RX_DATA_AV_IRQ — Writing 1 to this register does set the corresponding IRQ STATUS flag
  [26] RX_BUFFER_OVERFLOW_IRQ — Writing 1 to this register does set the corresponding IRQ STATUS flag
  [25] TX_WATERLEVEL_IRQ — Writing 1 to this register does set the corresponding IRQ STATUS flag
  [24] RX_WATERLEVEL_IRQ — Writing 1 to this register does set the corresponding IRQ STATUS flag
  [22] RX_SC_DET_IRQ — Writing 1 to this register does set the corresponding IRQ STATUS flag
  [21] RX_SOF_DET_IRQ — Writing 1 to this register does set the corresponding IRQ STATUS flag
  [20] RX_EMD_IRQ — Writing 1 to this register does set the corresponding IRQ STATUS flag
  [n+16] TIMER{n}_IRQ (n=0..3) — Writing 1 to this register does set the corresponding IRQ STATUS flag
  [15] CLOCK_ERROR_IRQ — Writing 1 to this register does set the corresponding IRQ STATUS flag
  [14] INTERNAL_USE_14_14 — Internal Use
  [13] INTERNAL_USE_13_13 — Internal Use
  [12] RF_ACTIVE_ERROR_IRQ — Writing 1 to this register does set the corresponding IRQ STATUS flag
  [11] TX_RFON_IRQ — Writing 1 to this register does set the corresponding IRQ STATUS flag
  [10] TX_RFOFF_IRQ — Writing 1 to this register does set the corresponding IRQ STATUS flag
  [9] RFON_DET_IRQ — Writing 1 to this register does set the corresponding IRQ STATUS flag
  [8] RFOFF_DET_IRQ — Writing 1 to this register does set the corresponding IRQ STATUS flag
  [5] STATE_CHANGE_IRQ — Writing 1 to this register does set the corresponding IRQ STATUS flag
  [4] CARD_ACTIVATED_IRQ — Writing 1 to this register does set the corresponding IRQ STATUS flag
  [3] MODE_DETECTED_IRQ — Writing 1 to this register does set the corresponding IRQ STATUS flag
  [2] IDLE_IRQ — Writing 1 to this register does set the corresponding IRQ STATUS flag
  [1] TX_IRQ — Writing 1 to this register does set the corresponding IRQ STATUS flag
  [0] RX_IRQ — Writing 1 to this register does set the corresponding IRQ STATUS flag
